AUTOSAR XML (schema 4-2-1)
package /ComponentTypes
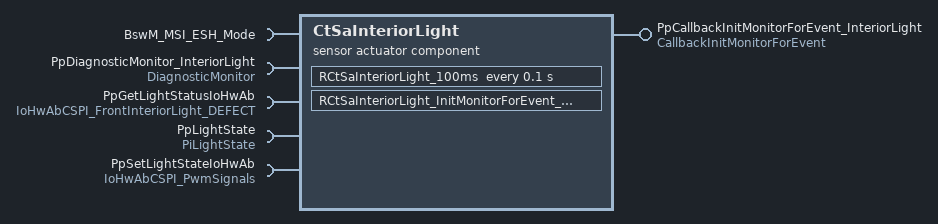
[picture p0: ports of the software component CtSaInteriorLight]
  sensor actuator sw component type CtSaInteriorLight
    provide port PpCallbackInitMonitorForEvent_InteriorLight: server-com-spec{operation=InitMonitorForEvent, queue-length=1}, provided-interface=CallbackInitMonitorForEvent
    5 x require port:
      BswM_MSI_ESH_Mode: mode-switch-receiver-com-spec{enhanced-mode-api=false, supports-asynchronous-mode-switch=false}, required-interface=BswM_MSI_ESH_Mode
      PpDiagnosticMonitor_InteriorLight: required-interface=DiagnosticMonitor
        required-com-specs:
          GetDTCOfEvent
          GetEventExtendedDataRecordEx
          GetEventFailed
          GetEventFreezeFrameDataEx
          GetEventStatus
          GetEventTested
          GetEventUdsStatus
          GetFaultDetectionCounter
          ResetEventDebounceStatus
          ResetEventStatus
          SetEventStatus
      PpGetLightStatusIoHwAb: required-com-specs=[IoHwAb_Get_FrontInteriorLight, IoHwAb_Set_FrontInteriorLight], required-interface=IoHwAbCSPI_FrontInteriorLight_DEFECT
      PpLightState: nonqueued-receiver-com-spec{data-element=DeLightState, filter=data-filter-type=ALWAYS, init-value=constant-reference=CLightOff}, required-interface=PiLightState
      PpSetLightStateIoHwAb: client-com-spec=IoHwAb_Set_Pwm_Signals, required-interface=IoHwAbCSPI_PwmSignals
    behavior CtSaInteriorLight_InternalBehavior: data-type-mapping=DemoTypeMapping, supports-multiple-instantiation=true
      timing event TMT_RCtSaInteriorLightSwitchLight: start-on-event=RCtSaInteriorLight_100ms, period=0.1
        disabled-mode:
          BswM_MSI_ESH_Mode.BswM_MDGP_ESH_Mode.SHUTDOWN
          BswM_MSI_ESH_Mode.BswM_MDGP_ESH_Mode.STARTUP
          BswM_MSI_ESH_Mode.BswM_MDGP_ESH_Mode.WAKEUP
      operation invoked event OIT_PpCallbackInitMonitorForEvent_InteriorLight_InitMonitorForEvent_PpCallbackInitMonitorForEvent_InteriorLight_InitMoni46A49C32: start-on-event=RCtSaInteriorLight_InitMonitorForEvent_InteriorLight, operation=PpCallbackInitMonitorForEvent_InteriorLight.InitMonitorForEvent
      runnable RCtSaInteriorLight_100ms
        data-receive-point-by-arguments:
          access REC_FrontLightState_Element: accessed-variable=PpLightState.DeLightState
        sync call SC_PpDiagnosticMonitor_InteriorLight_SetEventStatus: operation=PpDiagnosticMonitor_InteriorLight.SetEventStatus, timeout=0
        sync call SC_PpGetLightStatusIoHwAb_IoHwAb_Get_FrontInteriorLight: operation=PpGetLightStatusIoHwAb.IoHwAb_Get_FrontInteriorLight, timeout=0
        sync call SC_PpSetLightStateIoHwAb_IoHwAb_Set_Pwm_Signals: operation=PpSetLightStateIoHwAb.IoHwAb_Set_Pwm_Signals, timeout=0
      runnable RCtSaInteriorLight_InitMonitorForEvent_InteriorLight
  swc implementation CtSaInteriorLight_Implementation: behavior=CtSaInteriorLight_InternalBehavior
    code-descriptors:
      code Default: artifact-descriptors=autosar-engineering-object={short-label=Default, category=SWSRC}
